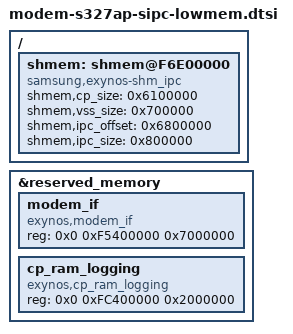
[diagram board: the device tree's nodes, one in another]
/*
 * SAMSUNG UNIVERSAL7885 board device tree source
 *
 * Copyright (c) 2016 Samsung Electronics Co., Ltd.
 *             http://www.samsung.com
 *
 * This program is free software; you can redistribute it and/or modify
 * it under the terms of the GNU General Public License version 2 as
 * published by the Free Software Foundation.
*/

/ {
	fragment@modemif {
		target-path = "/";
		__overlay__ {
			shmem: shmem@F6E00000 {
				compatible = "samsung,exynos-shm_ipc";

				shmem,cp_size = <0x6100000>; /* CP 97MB */
				shmem,vss_size = <0x700000>; /* VSS 7MB */
				shmem,ipc_offset = <0x6800000>; /* 104MB(CP 97MB + VSS 7MB) */
				shmem,ipc_size = <0x800000>; /* 8MB */
			};
		};
	};
};

&reserved_memory {
	#address-cells = <2>;
	#size-cells = <1>;
	/delete-node/ modem_if;

	modem_if {
		compatible = "exynos,modem_if";
		reg = <0x0 0xF5400000 0x7000000>;
	};

	cp_ram_logging {
		compatible = "exynos,cp_ram_logging";
		reg = <0x0 0xFC400000 0x2000000>;
	};
};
